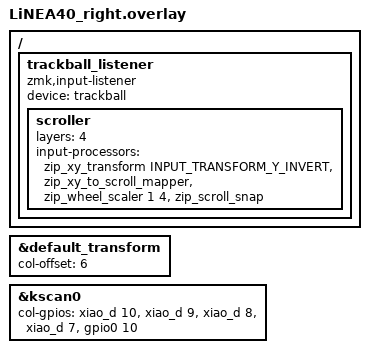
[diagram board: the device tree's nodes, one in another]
#include "LiNEA40.dtsi"
#include <dt-bindings/zmk/input_transform.h>

&default_transform {
    col-offset = <6>;
};

&kscan0 {
    col-gpios
        = <&xiao_d 10 GPIO_ACTIVE_HIGH>
        , <&xiao_d 9 GPIO_ACTIVE_HIGH>
        , <&xiao_d 8 GPIO_ACTIVE_HIGH>
        , <&xiao_d 7 GPIO_ACTIVE_HIGH>
        , <&gpio0 10 GPIO_ACTIVE_HIGH>
        ;
};

/ {
    trackball_listener: trackball_listener {
        compatible = "zmk,input-listener";
        status = "okay";
        device = <&trackball>;

        scroller {
            layers = <4>;

            input-processors = <
                &zip_xy_transform INPUT_TRANSFORM_Y_INVERT
                &zip_xy_to_scroll_mapper
                &zip_wheel_scaler 1 4
                &zip_scroll_snap
            >;
        };
    };
};
